AUTOSAR XML (schema 4-3-0)
package /App_WCT
  sender receiver interface IF_WCT  # NFC SWC Output
    data WCT_STR: type=IDT_WCT_STR
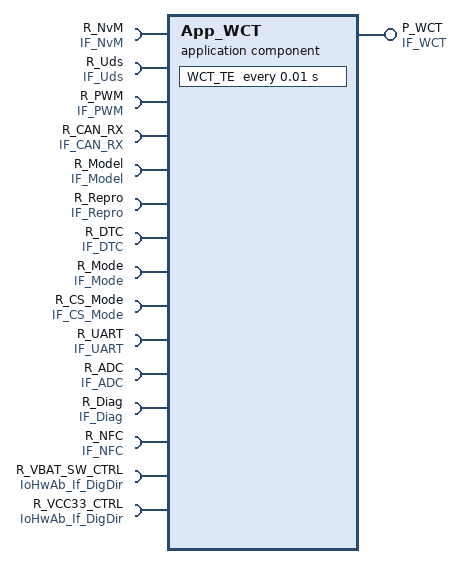
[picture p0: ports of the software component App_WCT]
  application sw component type App_WCT
    provide port P_WCT: nonqueued-sender-com-spec=WCT_STR, provided-interface=IF_WCT
    15 x require port:
      R_NvM: nonqueued-receiver-com-spec=NvM_STR, required-interface=IF_NvM
      R_Uds: nonqueued-receiver-com-spec=Uds_STR, required-interface=IF_Uds
      R_PWM: nonqueued-receiver-com-spec=PWM_STR, required-interface=IF_PWM
      R_CAN_RX: nonqueued-receiver-com-spec=CAN_RX_STR, required-interface=IF_CAN_RX
      R_Model: nonqueued-receiver-com-spec=Model_STR, required-interface=IF_Model
      R_Repro: nonqueued-receiver-com-spec=Repro_STR, required-interface=IF_Repro
      R_DTC: nonqueued-receiver-com-spec=DTC_STR, required-interface=IF_DTC
      R_Mode: nonqueued-receiver-com-spec=Mode_STR, required-interface=IF_Mode
      R_CS_Mode: required-com-specs=[ModeInit, NvMInit, ApplicationInit], required-interface=IF_CS_Mode
      R_UART: nonqueued-receiver-com-spec=UART_STR, required-interface=IF_UART
      R_ADC: nonqueued-receiver-com-spec=ADC_STR, required-interface=IF_ADC
      R_Diag: nonqueued-receiver-com-spec=Diag_STR, required-interface=IF_Diag
      R_NFC: nonqueued-receiver-com-spec=NFC_STR, required-interface=IF_NFC
      R_VBAT_SW_CTRL: client-com-spec=WriteDirect, required-interface=IoHwAb_If_DigDir
      R_VCC33_CTRL: client-com-spec=WriteDirect, required-interface=IoHwAb_If_DigDir
    behavior InternalBehavior: data-type-mapping=DataTypeMappingSet_WPC
      timing event TE_WCT_TE: start-on-event=WCT_TE, period=0.01
      runnable WCT_TE: symbol=WCT_TE_Runnable
        data-receive-point-by-arguments:
          12 x access, all with scope=COMMUNICATION-INTER-ECU:
            DRPBA_WCT_TE_R_ADC_Structure: accessed-variable=R_ADC.ADC_STR
            DRPBA_WCT_TE_R_BCAN_RX_Structure: accessed-variable=R_CAN_RX.CAN_RX_STR
            DRPBA_WCT_TE_R_Mode_Structure: accessed-variable=R_Mode.Mode_STR
            DRPBA_WCT_TE_R_Model_Structure: accessed-variable=R_Model.Model_STR
            DRPBA_WCT_TE_R_Repro_Structure: accessed-variable=R_Repro.Repro_STR
            DRPBA_WCT_TE_R_UART_Structure: accessed-variable=R_UART.UART_STR
            DRPBA_WCT_TE_R_PWM_PWM_STR: accessed-variable=R_PWM.PWM_STR
            DRPBA_WCT_TE_R_Diag_Diag_STR: accessed-variable=R_Diag.Diag_STR
            DRPBA_WCT_TE_R_NFC_NFC2_STR: accessed-variable=R_NFC.NFC_STR
            DRPBA_WCT_TE_R_DTC_DTC_STR: accessed-variable=R_DTC.DTC_STR
            DRPBA_WCT_TE_R_Uds_Uds_STR: accessed-variable=R_Uds.Uds_STR
            DRPBA_WCT_TE_R_NvM_NvM_STR: accessed-variable=R_NvM.NvM_STR
        data-send-points:
          access DSP_WCT_TE_P_WCT_WCT_STR_ALL: accessed-variable=P_WCT.WCT_STR, scope=COMMUNICATION-INTER-ECU
        5 x sync call:
          SSCP_WCT_TE_R_CS_Mode_ApplicationInit: operation=R_CS_Mode.ApplicationInit
          SSCP_WCT_TE_R_CS_Mode_ModeInit: operation=R_CS_Mode.ModeInit
          SSCP_WCT_TE_R_CS_Mode_NvMInit: operation=R_CS_Mode.NvMInit
          SSCP_WCT_TE_R_VBAT_SW_CTRL_WriteDirect: operation=R_VBAT_SW_CTRL.WriteDirect
          SSCP_WCT_TE_R_VCC33_CTRL_WriteDirect: operation=R_VCC33_CTRL.WriteDirect
